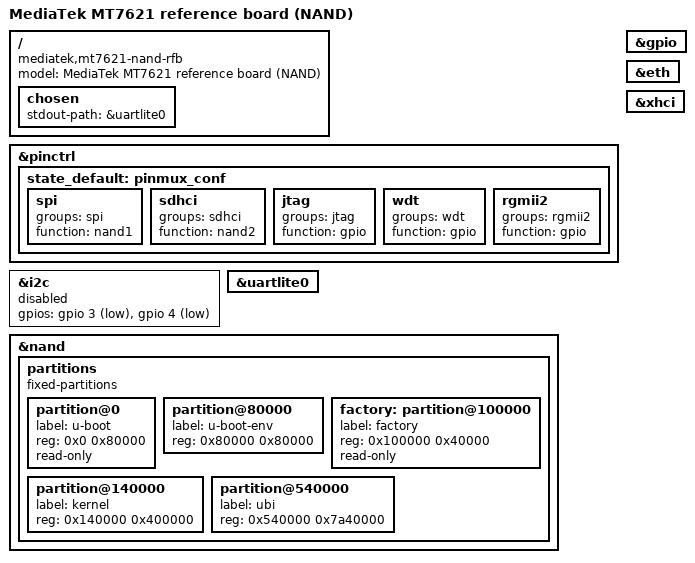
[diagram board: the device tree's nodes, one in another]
// SPDX-License-Identifier: GPL-2.0+
/*
 * Copyright (C) 2018 MediaTek Inc.
 *
 * Author: Weijie Gao <weijie.gao@mediatek.com>
 */

/dts-v1/;
#include "mt7621.dtsi"

/ {
	model = "MediaTek MT7621 reference board (NAND)";
	compatible = "mediatek,mt7621-nand-rfb", "mediatek,mt7621-soc";

	chosen {
		stdout-path = &uartlite0;
	};
};

&pinctrl {
	state_default: pinmux_conf {
		spi {
			groups = "spi";
			function = "nand1";
		};

		sdhci {
			groups = "sdhci";
			function = "nand2";
		};

		jtag {
			groups = "jtag";
			function = "gpio";
		};

		wdt {
			groups = "wdt";
			function = "gpio";
		};

		rgmii2 {
			groups = "rgmii2";
			function = "gpio";
		};
	};
};

&gpio {
	status = "okay";
};

&i2c {
	gpios = <&gpio 3 1>, /* PIN3 as SDA */
		<&gpio 4 1>; /* PIN4 as CLK */
	status = "disabled";
};

&uartlite0 {
	status = "okay";
};

&eth {
	status = "okay";
};

&xhci {
	status = "okay";
};

&nand {
	status = "okay";

	partitions {
		compatible = "fixed-partitions";
		#address-cells = <1>;
		#size-cells = <1>;

		partition@0 {
			label = "u-boot";
			reg = <0x0 0x80000>;
			read-only;
		};

		partition@80000 {
			label = "u-boot-env";
			reg = <0x80000 0x80000>;
		};

		factory: partition@100000 {
			label = "factory";
			reg = <0x100000 0x40000>;
			read-only;
		};

		partition@140000 {
			label = "kernel";
			reg = <0x140000 0x400000>;
		};

		partition@540000 {
			label = "ubi";
			reg = <0x540000 0x7a40000>;
		};
	};
};
